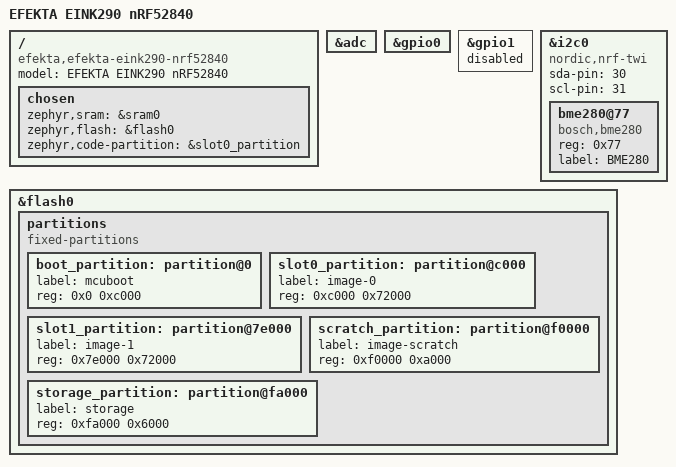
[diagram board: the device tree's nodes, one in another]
// Copyright (c) 2021 Nordic Semiconductor ASA
// SPDX-License-Identifier: Apache-2.0

/dts-v1/;
#include <nordic/nrf52840_qiaa.dtsi>

/ {
	model = "EFEKTA EINK290 nRF52840";
	compatible = "efekta,efekta-eink290-nrf52840";
	
	chosen {
		zephyr,sram = &sram0;
		zephyr,flash = &flash0;
		zephyr,code-partition = &slot0_partition;
	};
	/* leds {
		compatible = "gpio-leds";
		led0: led_0 {
			gpios = <&gpio0 2 GPIO_ACTIVE_LOW>;
			label = "LED 0";
		};
	};
	
	buttons {
		compatible = "gpio-keys";
		button0: button_0 {
			gpios = <&gpio0 24 (GPIO_PULL_UP | GPIO_ACTIVE_LOW)>;
			label = "Push button switch 0";
		};
	};
	aliases {
		led0 = &led0;
		sw0 = &button0;
		bootloader-led0 = &led0;
	}; */
};


&adc {
    status = "okay";
};

&gpio0 {
	status = "okay";
};

&gpio1 {
	status = "disabled";
};



&i2c0 {

	compatible = "nordic,nrf-twi";
		status = "okay";
		sda-pin = <30>; ////<28>;
		scl-pin = <31>; ////<3>;
		
/* 		max44009@4a {
			compatible = "maxim,max44009";
			reg = <0x4a>;
			//int-gpios = <&gpio0 29 0>;
			label = "MAX44009";
		}; */

		bme280@77 {
			compatible = "bosch,bme280";
			reg = <0x77>;
			label = "BME280";
		};
}; 


&flash0 {
	partitions {
		compatible = "fixed-partitions";
		#address-cells = <1>;
		#size-cells = <1>;

		boot_partition: partition@0 {
			label = "mcuboot";
			reg = <0x0 0xc000>;
		};
		slot0_partition: partition@c000 {
			label = "image-0";
			reg = <0xc000 0x72000>;
		};
		slot1_partition: partition@7e000 {
			label = "image-1";
			reg = <0x7e000 0x72000>;
		};
		scratch_partition: partition@f0000 {
			label = "image-scratch";
			reg = <0xf0000 0xa000>;
		};
		storage_partition: partition@fa000 {
			label = "storage";
			reg = <0xfa000 0x6000>;
		};
	};
};

